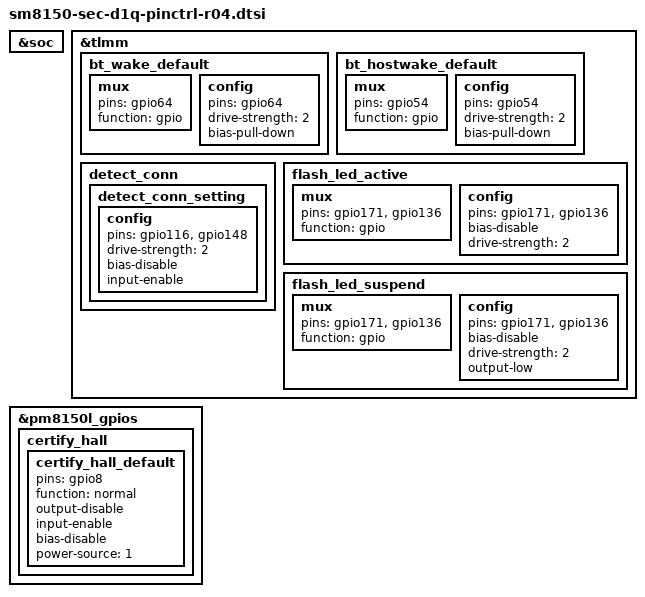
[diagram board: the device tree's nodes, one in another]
/* Copyright (c) 2016-2017, The Linux Foundation. All rights reserved.
 *
 * This program is free software; you can redistribute it and/or modify
 * it under the terms of the GNU General Public License version 2 and
 * only version 2 as published by the Free Software Foundation.
 *
 * This program is distributed in the hope that it will be useful,
 * but WITHOUT ANY WARRANTY; without even the implied warranty of
 * MERCHANTABILITY or FITNESS FOR A PARTICULAR PURPOSE.  See the
 * GNU General Public License for more details.
 */

#include "sm8150-sec-d1q-pinctrl-common.dtsi"

&soc {
	/* tlmm: pinctrl@03400000 { }; */
};

&tlmm {
	bt_wake_default: bt_wake_default {
		mux {
			pins = "gpio64";
			function = "gpio";
		};
		config {
			pins = "gpio64";
			drive-strength = <2>;
			bias-pull-down;
		};
	};
	bt_hostwake_default: bt_hostwake_default {
		mux {
			pins = "gpio54";
			function = "gpio";
		};
		config {
			pins = "gpio54";
			drive-strength = <2>;
			bias-pull-down;
		};
	};

	detect_conn {
		detect_conn_setting: detect_conn_setting {
			config {
				pins = "gpio116", "gpio148";
				drive-strength = <2>;
				bias-disable; /* No PULL */
				input-enable;
			};
		};
	};

	flash_led_active: flash_led_active {
		mux {
			pins = "gpio171","gpio136";
			function = "gpio";
		};

		config {
			pins = "gpio171","gpio136";
			bias-disable; /* No PULL */
			drive-strength = <2>; /* 2 MA */
		};
	};

	flash_led_suspend: flash_led_suspend {
		mux {
			pins = "gpio171","gpio136";
			function = "gpio";
		};

		config {
			pins = "gpio171","gpio136";
			bias-disable; /* No PULL */
			drive-strength = <2>; /* 2 MA */
			output-low;
		};
	};
};

&pm8150l_gpios {
	certify_hall {
		certify_hall_default: certify_hall_default {
			pins = "gpio8";
			function = "normal";
			output-disable;
			input-enable;
			bias-disable;
			power-source = <1>;
		};
	};
};
